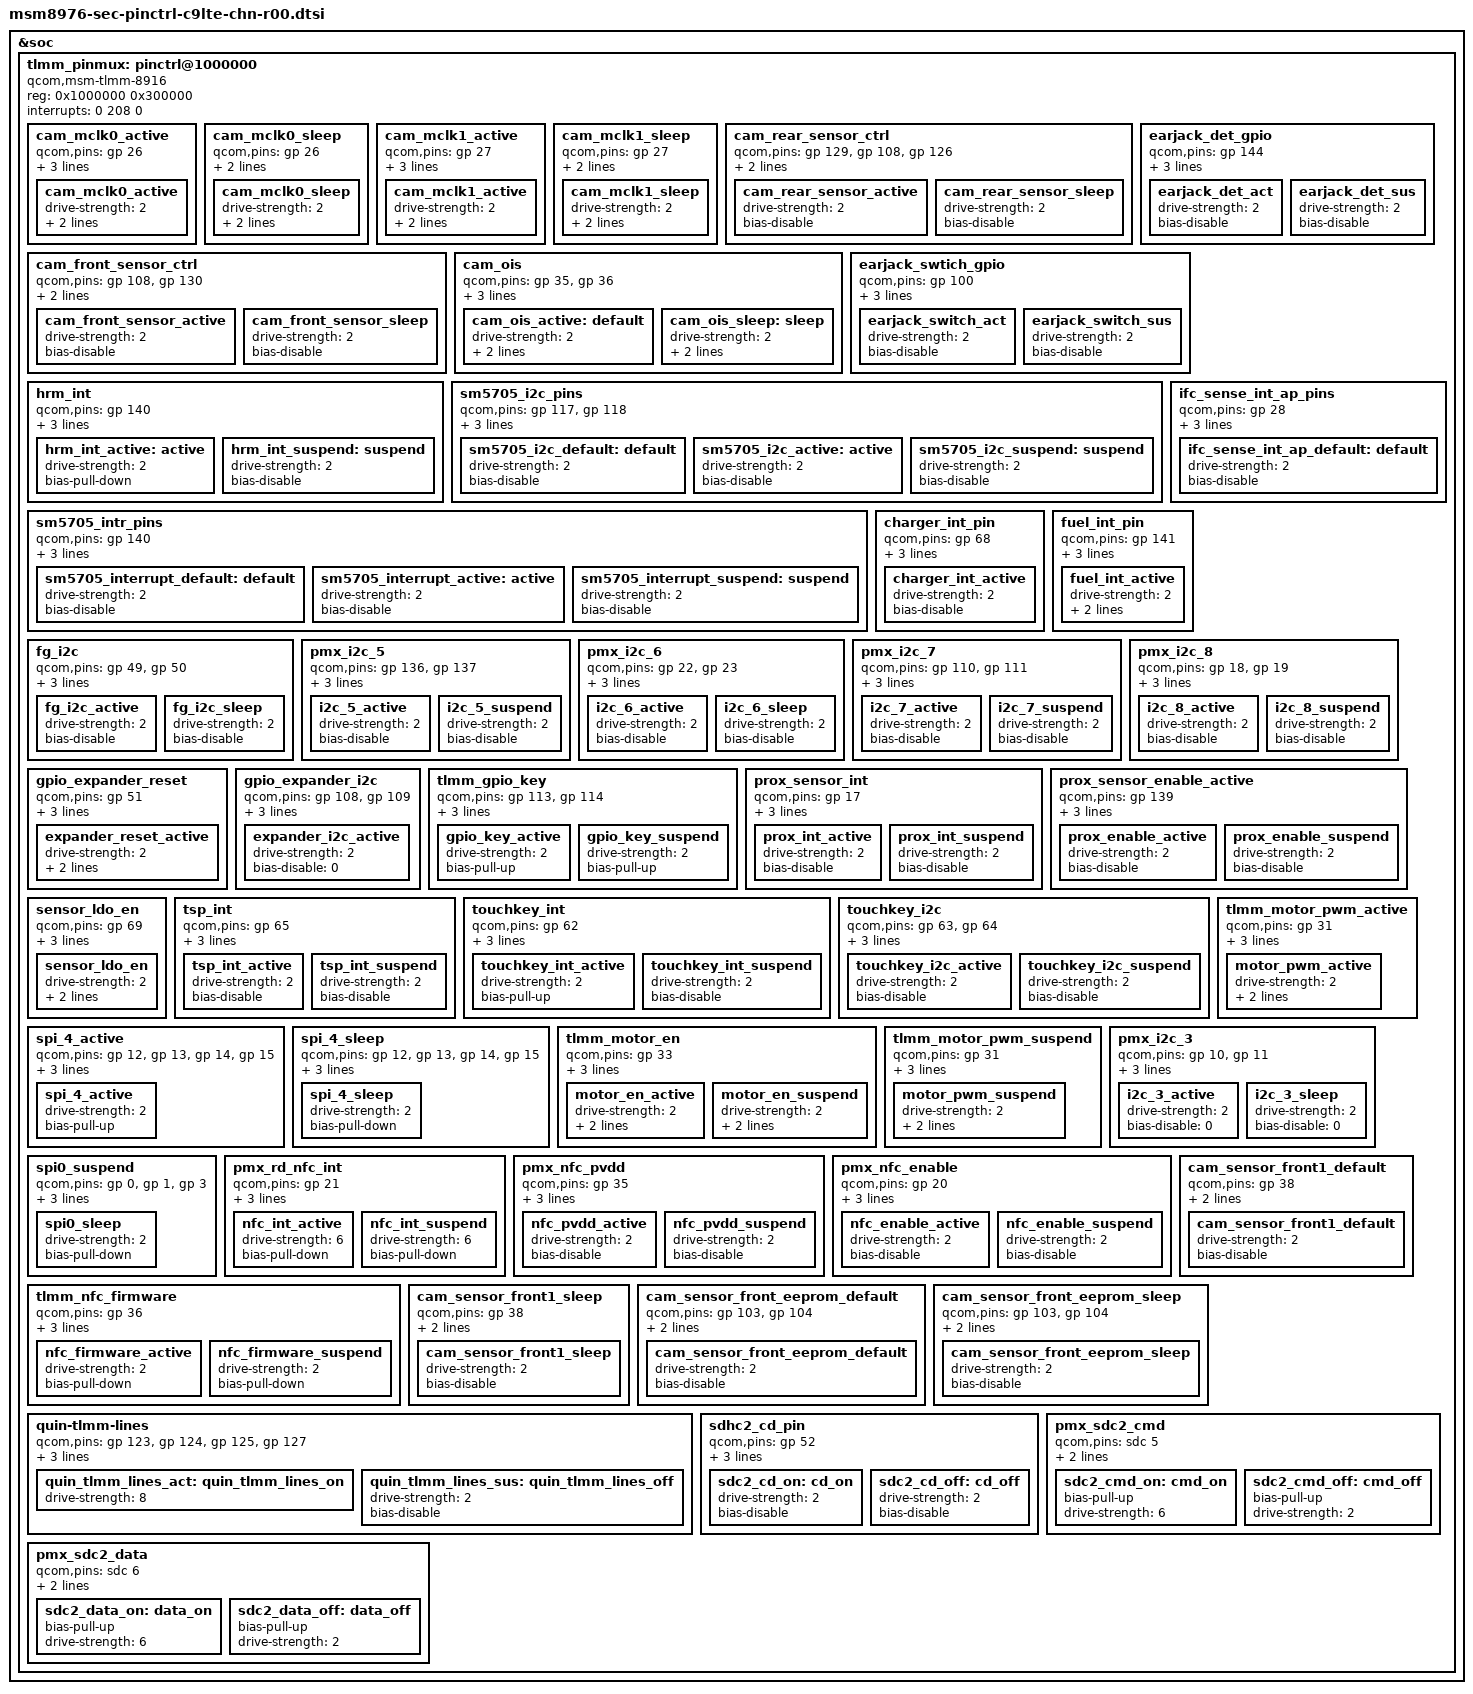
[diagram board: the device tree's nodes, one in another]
/*
 * Copyright (c) 2014-2015, The Linux Foundation. All rights reserved.
 *
 * This program is free software; you can redistribute it and/or modify
 * it under the terms of the GNU General Public License version 2 and
 * only version 2 as published by the Free Software Foundation.
 *
 * This program is distributed in the hope that it will be useful,
 * but WITHOUT ANY WARRANTY; without even the implied warranty of
 * MERCHANTABILITY or FITNESS FOR A PARTICULAR PURPOSE.  See the
 * GNU General Public License for more details.
 */

/* Pinctrl device tree file for a9xprolte chn open REV0.1 */

&tlmm_pinmux {
		/* MUIC - SM5705 */
		sm5705_i2c_pins {
			qcom,pins = <&gp 117>, <&gp 118>; /* SDA, SCL */
			qcom,num-grp-pins = <2>;
			qcom,pin-func = <0>;
			label = "sm5705_gpio";
			sm5705_i2c_default: default {
				drive-strength = <2>;
				bias-disable;
			};
			sm5705_i2c_active: active {
				drive-strength = <2>;
				bias-disable;
			};
			sm5705_i2c_suspend: suspend {
				drive-strength = <2>;
				bias-disable;
			};
		};

		sm5705_intr_pins {
			qcom,pins = <&gp 140>;
			qcom,num-grp-pins = <1>;
			qcom,pin-func = <0>;
			label = "sm5705_gpio_int";
			sm5705_interrupt_default: default {
				drive-strength = <2>;
				bias-disable;
			};
			sm5705_interrupt_active: active {
				drive-strength = <2>;
				bias-disable;
			};
			sm5705_interrupt_suspend: suspend {
				drive-strength = <2>;
				bias-disable;
			};
		};

		ifc_sense_int_ap_pins {
			qcom,pins = <&gp 28>;
			qcom,num-grp-pins = <1>;
			qcom,pin-func = <0>;
			label = "ifc_sense_int_ap";
			ifc_sense_int_ap_default: default {
				drive-strength = <2>;
				bias-disable;
			};
		};

		charger_int_pin {
			qcom,pins = <&gp 68>;
			qcom,num-grp-pins = <1>;
			qcom,pin-func = <0>;
			label = "charger_int_gpio";
			charger_int_active: charger_int_active {
				drive-strength = <2>;
				bias-disable;         /* No PULL */
			};
		};

		fuel_int_pin {
			qcom,pins = <&gp 141>;
			qcom,num-grp-pins = <1>;
			qcom,pin-func = <0>;
			label = "fuel_int_gpio";
			fuel_int_active: fuel_int_active {
				drive-strength = <2>;
				bias-disable;         /* No PULL */
				input-enable;
			};
		};

		fg_i2c {
			/* CLK, DATA */
			qcom,pins = <&gp 49>, <&gp 50>;
			qcom,num-grp-pins = <2>;
			qcom,pin-func = <0>;
			label = "fg_i2c";

			fg_i2c_active: fg_i2c_active {
				drive-strength = <2>;	/* 2 MA */
				bias-disable; /* No PULL */
			};

			fg_i2c_sleep: fg_i2c_sleep {
				drive-strength = <2>;	/* 2 MA */
				bias-disable; /* No PULL */
			};
		};

		pmx_i2c_5 {
			/* CLK, DATA */
			qcom,pins = <&gp 136>, <&gp 137>;
			qcom,num-grp-pins = <2>;
			qcom,pin-func = <3>;
			label = "pmx_i2c_5";
			/* active state */
			i2c_5_active: i2c_5_active{
				drive-strength = <2>;
				bias-disable;
			};
			/* suspend state */
			i2c_5_suspend: i2c_5_suspend {
				drive-strength = <2>;
				bias-disable;
			};
		};

		pmx_i2c_6 {
			/* CLK, DATA */
			qcom,pins = <&gp 22>, <&gp 23>;
			qcom,num-grp-pins = <2>;
			qcom,pin-func = <3>;
			label = "pmx_i2c_6";
			/* active state */
			i2c_6_active: i2c_6_active{
				drive-strength = <2>; /* 2 MA */
				bias-disable; /* No PULL */
			};
			/* suspend state */
			i2c_6_sleep: i2c_6_sleep {
				drive-strength = <2>; /* 2 MA */
				bias-disable; /* No PULL */
			};
		};

		pmx_i2c_7 {
			/* CLK, DATA */
			qcom,pins = <&gp 110>, <&gp 111>;
			qcom,num-grp-pins = <2>;
			qcom,pin-func = <3>;
			label = "pmx_i2c_7";
			/* active state */
			i2c_7_active: i2c_7_active{
				drive-strength = <2>;
				bias-disable;
			};
			/* suspend state */
			i2c_7_suspend: i2c_7_suspend {
				drive-strength = <2>;
				bias-disable;
			};
		};

		pmx_i2c_8 {
			/* CLK, DATA */
			qcom,pins = <&gp 18>, <&gp 19>;
			qcom,num-grp-pins = <2>;
			qcom,pin-func = <3>;
			label = "pmx_i2c_8";
			/* active state */
			i2c_8_active: i2c_8_active{
				drive-strength = <2>;
				bias-disable;
			};
			/* suspend state */
			i2c_8_suspend: i2c_8_suspend {
				drive-strength = <2>;
				bias-disable;
			};
		};
		
		gpio_expander_reset {
			qcom,pins = <&gp 51>;
			qcom,pin-func = <0>;
			qcom,num-grp-pins = <1>;
			label = "gpio_expander_reset";
			expander_reset_active: expander_reset_active {
				drive-strength = <2>;
				output-high;
				bias-disable = <0>; /* No PULL */
			};
		};

		gpio_expander_i2c {
			qcom,pins = <&gp 108>, <&gp 109>;
			qcom,pin-func = <0>;
			qcom,num-grp-pins = <2>;
			label = "gpio_expander_i2c";
			expander_i2c_active: expander_i2c_active {
				drive-strength = <2>;
				bias-disable = <0>; /* No PULL */
			};
		};

		tlmm_gpio_key {
			qcom,pins = <&gp 113>, <&gp 114>;
			qcom,pin-func = <0>;
			qcom,num-grp-pins = <2>;
			label = "tlmm_gpio_key";
			gpio_key_active: gpio_key_active {
				drive-strength = <2>;
				bias-pull-up;
			};
			gpio_key_suspend: gpio_key_suspend {
				drive-strength = <2>;
				bias-pull-up;
			};
		};

		/* add pingrp for proximity sensors  */
		prox_sensor_int {
			qcom,pins = <&gp 17>;
			qcom,pin-func = <3>;
			qcom,num-grp-pins = <1>;
			label = "prox_sensor_int";
			prox_int_active: prox_int_active {
				drive-strength = <2>;
				bias-disable; /* No PULL */
			};
			prox_int_suspend: prox_int_suspend {
				drive-strength = <2>;
				bias-disable; /* No PULL */
			};
		};

		prox_sensor_enable_active {
			qcom,pins = <&gp 139>;
			qcom,pin-func = <0>;
			qcom,num-grp-pins = <1>;
			label = "prox_sensor_enable_active";
			prox_enable_active: prox_enable_active {
				drive-strength = <2>;
				bias-disable; /* No PULL */
			};
			prox_enable_suspend: prox_enable_suspend {
				drive-strength = <2>;
				bias-disable; /* No PULL */
			};
		};

		sensor_ldo_en {
			qcom,pins = <&gp 69>;
			qcom,pin-func = <0>;
			qcom,num-grp-pins = <1>;
			label = "sensor_ldo_en";
			sensor_ldo_en: sensor_ldo_en {
				drive-strength = <2>;
				output-high;
				bias-disable = <0>; /* No PULL */
			};
		};

		tsp_int {
			qcom,pins = <&gp 65>; /* INTERRUPT */
			qcom,num-grp-pins = <1>;
			qcom,pin-func = <0>;
			label = "tsp_int";
			tsp_int_active: tsp_int_active {
				drive-strength = <2>;
				bias-disable;
			};
			tsp_int_suspend: tsp_int_suspend {
				drive-strength = <2>;
				bias-disable;
			};
		};

		touchkey_int {
			qcom,pins = <&gp 62>; /* INTERRUPT */
			qcom,num-grp-pins = <1>;
			qcom,pin-func = <0>;
			label = "touchkey_int";
			touchkey_int_active: touchkey_int_active {
				drive-strength = <2>;
				bias-pull-up;
			};
			touchkey_int_suspend: touchkey_int_suspend {
				drive-strength = <2>;
				bias-disable;
			};
		};

		touchkey_i2c {
			qcom,pins = <&gp 63>, <&gp 64>; /* SDA, SCL */
			qcom,num-grp-pins = <2>;
			qcom,pin-func = <0>;
			label = "touchkey_i2c";
			touchkey_i2c_active: touchkey_i2c_active {
				drive-strength = <2>;
				bias-disable;
			};
			touchkey_i2c_suspend: touchkey_i2c_suspend {
				drive-strength = <2>;
				bias-disable;
			};
		};

		spi_4_active {
			qcom,pins = <&gp 12>, <&gp 13>, <&gp 14>, <&gp 15>;
			qcom,pin-func = <1>;
			qcom,num-grp-pins = <4>;
			label = "spi_4";
			spi_4_active: spi_4_active {
				drive-strength = <2>;
				bias-pull-up;
			};
		};

		spi_4_sleep {
			qcom,pins = <&gp 12>, <&gp 13>, <&gp 14>, <&gp 15>;
			qcom,pin-func = <0>;
			qcom,num-grp-pins = <4>;
			label = "spi_4";
			spi_4_sleep: spi_4_sleep {
				drive-strength = <2>;
				bias-pull-down;
			};
		};

		tlmm_motor_en {
			qcom,pins = <&gp 33>;
			qcom,pin-func = <0>;
			qcom,num-grp-pins = <1>;
			label = "tlmm_motor_en";
			motor_en_active: motor_en_active {
				drive-strength = <2>;
				bias-disable = <0>; /* No PULL */
				output-high;
			};
			motor_en_suspend: motor_en_suspend {
				drive-strength = <2>;
				bias-disable = <0>; /* No PULL */
				output-low;
			};
		};

		tlmm_motor_pwm_active {
			qcom,pins = <&gp 31>;
			qcom,pin-func = <2>;
			qcom,num-grp-pins = <1>;
			label = "motor_pwm_active";
			motor_pwm_active: motor_pwm_active {
				drive-strength = <2>;
				bias-disable; /* NO PULL */
				output-high;
			};
		};

		tlmm_motor_pwm_suspend {
			qcom,pins = <&gp 31>;
			qcom,pin-func = <0>;
			qcom,num-grp-pins = <1>;
			label = "motor_pwm_suspend";
			motor_pwm_suspend: motor_pwm_suspend {
				drive-strength = <2>;
				bias-pull-down; /* PULL DOWN */
				output-low;
			};
		};

		pmx_i2c_3 {
			/* CLK, DATA */
			qcom,pins = <&gp 10>, <&gp 11>;
			qcom,num-grp-pins = <2>;
			qcom,pin-func = <3>;
			label = "pmx_i2c_3";
			/* active state */
			i2c_3_active: i2c_3_active {
				drive-strength = <2>; /* 2 MA */
				bias-disable = <0>; /* No PULL */
			};
			/* suspend state */
			i2c_3_sleep: i2c_3_sleep {
				drive-strength = <2>; /* 2 MA */
				bias-disable = <0>; /* No PULL */
			};
		};

		/delete-node/ pmx_rd_nfc_int;
		/delete-node/ spi0_suspend;

		spi0_suspend {
                        /* MOSI, MISO, CLK */
                        qcom,pins = <&gp 0>, <&gp 1>, <&gp 3>;
                        qcom,num-grp-pins = <3>;
                        qcom,pin-func = <0>;
                        label = "spi0-suspend";
                        /* suspended state */
                        spi0_sleep: spi0_sleep {
                                drive-strength = <2>; /* 2 MA */
                                bias-pull-down; /* PULL DOWN */
                        };
                };

		pmx_rd_nfc_int {
			qcom,pins = <&gp 21>;
			qcom,pin-func = <0>;
			qcom,num-grp-pins = <1>;
			label = "pmx_nfc_int";

			nfc_int_active: nfc_int_active {
				drive-strength = <6>;
				bias-pull-down;
			};

			nfc_int_suspend: nfc_int_suspend {
				drive-strength = <6>;
				bias-pull-down;
			};
		};

		pmx_nfc_pvdd {
			qcom,pins = <&gp 35>;
			qcom,pin-func = <0>;
			qcom,num-grp-pins = <1>;
			label = "pmx_nfc_pvdd";

			nfc_pvdd_active: nfc_pvdd_active {
				drive-strength = <2>;
				bias-disable;
			};

			nfc_pvdd_suspend: nfc_pvdd_suspend {
				drive-strength = <2>;
				bias-disable;
			};
		};

		pmx_nfc_enable {
			qcom,pins = <&gp 20>;
			qcom,pin-func = <0>;
			qcom,num-grp-pins = <1>;
			label = "pmx_nfc_enable";

			nfc_enable_active: nfc_enable_active {
				drive-strength = <2>;
				bias-disable;
			};

			nfc_enable_suspend: nfc_enable_suspend {
				drive-strength = <2>;
				bias-disable;
			};
		};

		tlmm_nfc_firmware{
			qcom,pins = <&gp 36>;
			qcom,pin-func = <0>;
			qcom,num-grp-pins = <1>;
			label = "tlmm_nfc_firmware";

			nfc_firmware_active: nfc_firmware_active {
				drive-strength = <2>;
				bias-pull-down; /* PULL DOWN */
			};

			nfc_firmware_suspend: nfc_firmware_suspend {
				drive-strength = <2>;
				bias-pull-down; /* PULL DOWN */
			};
		};

		/delete-node/ cam_sensor_front1_default;
		/delete-node/ cam_sensor_front1_sleep;

		cam_sensor_front1_default {
			/* RESET, STANDBY */
			qcom,pins = /*<&gp 131>,*/ <&gp 38>;
			qcom,num-grp-pins = <1/*2*/>;
			label = "cam_sensor_front1_default";
			/* active state */
			cam_sensor_front1_default: cam_sensor_front1_default {
				drive-strength = <2>; /* 2 MA */
				bias-disable; /* No PULL */
			};
		};

		cam_sensor_front1_sleep {
			/* RESET, STANDBY */
			qcom,pins = /*<&gp 131>,*/ <&gp 38>;
			qcom,num-grp-pins = <1/*2*/>;
			label = "cam_sensor_front1_sleep";
			/*suspended state */
			cam_sensor_front1_sleep: cam_sensor_front1_sleep {
				drive-strength = <2>; /* 2 MA */
				bias-disable; /* No PULL */
			};
		};

		cam_sensor_front_eeprom_default {
			/* SDA, SCL */
			qcom,pins = <&gp 103>,<&gp 104>;
			qcom,num-grp-pins = <2>;
			label = "cam_sensor_front_eeprom_default";
			/* active state */
			cam_sensor_front_eeprom_default: cam_sensor_front_eeprom_default {
					 drive-strength = <2>; /* 2 MA */
					 bias-disable; /* No PULL */
			};
		};

		cam_sensor_front_eeprom_sleep {
			/* SDA, SCL */
			qcom,pins = <&gp 103>, <&gp 104>;
			qcom,num-grp-pins = <2>;
			label = "cam_sensor_front_eeprom_sleep";
			/*suspended state */
			cam_sensor_front_eeprom_sleep: cam_sensor_front_eeprom_sleep {
				       drive-strength = <2>; /* 2 MA */
				       bias-disable; /* No PULL */
			};
		};

		quin-tlmm-lines {
			qcom,pins = <&gp 123>, <&gp 124>, <&gp 125>, <&gp 127>;
			qcom,num-grp-pins = <4>;
			qcom,pin-func = <1>;
			label = "quin-tlmm-lines";
			quin_tlmm_lines_act: quin_tlmm_lines_on {
				drive-strength = <8>;
			};
			quin_tlmm_lines_sus: quin_tlmm_lines_off {
				drive-strength = <2>;
				bias-disable;
			};
		};

		sdhc2_cd_pin {
			qcom,pins = <&gp 52>;
			qcom,num-grp-pins = <1>;
			qcom,pin-func = <0>;
			label = "cd-gpio";
			sdc2_cd_on: cd_on {
				drive-strength = <2>;
				bias-disable;
			};
			sdc2_cd_off: cd_off {
				drive-strength = <2>;
				bias-disable;
			};
		};

		pmx_sdc2_cmd {
			qcom,pins = <&sdc 5>;
			qcom,num-grp-pins = <1>;
			label = "sdc2-cmd";
			sdc2_cmd_on: cmd_on {
				bias-pull-up; /* pull up */
				drive-strength = <6>; /* 6 MA */
			};
			sdc2_cmd_off: cmd_off {
				bias-pull-up; /* pull up */
				drive-strength = <2>; /* 2 MA */
			};
		};

		pmx_sdc2_data {
			qcom,pins = <&sdc 6>;
			qcom,num-grp-pins = <1>;
			label = "sdc2-data";
			sdc2_data_on: data_on {
				bias-pull-up; /* pull up */
				drive-strength = <6>; /* 6 MA */
			};
			sdc2_data_off: data_off {
				bias-pull-up; /* pull up */
				drive-strength = <2>; /* 2 MA */
			};
		};


		/delete-node/ tpiu_seta_18;
		/delete-node/ pri-tlmm-lines;
};

&soc {
  tlmm_pinmux: pinctrl@1000000 {
    compatible = "qcom,msm-tlmm-8916";
    reg = <0x1000000 0x300000>;
    interrupts = <0 208 0>;


    cam_mclk0_active {
      qcom,pins = <&gp 26>;
      qcom,num-grp-pins = <1>;
      qcom,pin-func = <1>;
      label = "cam_mclk0_active";
      cam_mclk0_active: cam_mclk0_active{
        drive-strength = <2>; /* 2 MA */
        bias-disable; /* No PULL */
        output-low;
      };
    };
    cam_mclk0_sleep {
      qcom,pins = <&gp 26>;
      qcom,num-grp-pins = <1>;
      label = "cam_mclk0_sleep";
      cam_mclk0_sleep: cam_mclk0_sleep{
        drive-strength = <2>; /* 2 MA */
        bias-pull-down; /* PULL DOWN */
        output-low;
      };
    };

    cam_mclk1_active {
      qcom,pins = <&gp 27>;
      qcom,num-grp-pins = <1>;
      qcom,pin-func = <1>;
      label = "cam_mclk1_active";
      cam_mclk1_active: cam_mclk1_active{
        drive-strength = <2>; /* 2 MA */
        bias-disable; /* No PULL */
        output-low;
      };
    };
    cam_mclk1_sleep {
      qcom,pins = <&gp 27>;
      qcom,num-grp-pins = <1>;
      label = "cam_mclk1_sleep";
      cam_mclk1_sleep: cam_mclk1_sleep{
        drive-strength = <2>; /* 2 MA */
        bias-pull-down; /* PULL DOWN */
        output-low;
      };
    };


    cam_rear_sensor_ctrl {
      qcom,pins = <&gp 129>, <&gp 108>,<&gp 126>;
      qcom,num-grp-pins = <3>;
      label = "cam_rear_sensor_ctrl";
      cam_rear_sensor_active: cam_rear_sensor_active{
        drive-strength = <2>; /* 2 MA */
        bias-disable; /* No PULL */
      };
      cam_rear_sensor_sleep: cam_rear_sensor_sleep{
        drive-strength = <2>; /* 2 MA */
        bias-disable; /* No PULL */
      };
    };

    cam_front_sensor_ctrl {
      qcom,pins = <&gp 108>, <&gp 130>;
      qcom,num-grp-pins = <2>;
      label = "cam_front_sensor_ctrl";
      cam_front_sensor_active: cam_front_sensor_active{
        drive-strength = <2>; /* 2 MA */
        bias-disable; /* No PULL */
      };
      cam_front_sensor_sleep: cam_front_sensor_sleep{
        drive-strength = <2>; /* 2 MA */
        bias-disable; /* No PULL */
      };
    };

	cam_ois {
		qcom,pins = <&gp 35>, <&gp 36>;
		qcom,num-grp-pins = <2>;
		qcom,pin-func = <0>;
		label = "cam_ois";

		cam_ois_active: default {
			drive-strength = <2>;   /* 2 MA */
			bias-disable; /* No PULL */
			output-low;

		};

		cam_ois_sleep: sleep {
			drive-strength = <2>;   /* 2 MA */
			bias-disable; /* No PULL */
			output-low;
		};
	};

    earjack_det_gpio {
      qcom,pins = <&gp 144>;
      qcom,pin-func = <0>;
      qcom,num-grp-pins = <1>;
      label = "earjack_det_gpio";
      earjack_det_act: earjack_det_act {
            drive-strength = <2>;
            bias-disable;
      };
      earjack_det_sus: earjack_det_sus {
            drive-strength = <2>;
            bias-disable;
      };
    };
    earjack_swtich_gpio {
      qcom,pins = <&gp 100>;
      qcom,pin-func = <0>;
      qcom,num-grp-pins = <1>;
      label = "earjack_swtich_gpio";
      earjack_switch_act: earjack_switch_act {
            drive-strength = <2>;
            bias-disable;
      };
      earjack_switch_sus: earjack_switch_sus {
            drive-strength = <2>;
            bias-disable;
      };
    };

    hrm_int {
      qcom,pins = <&gp 140>;
      qcom,pin-func = <0>;
      qcom,num-grp-pins = <1>;
      label = "hrm_int";

      hrm_int_active: active {
	drive-strength = <2>;
	bias-pull-down;
      };

      hrm_int_suspend: suspend {
	drive-strength = <2>;
	bias-disable;
      };
    };

  };
};
